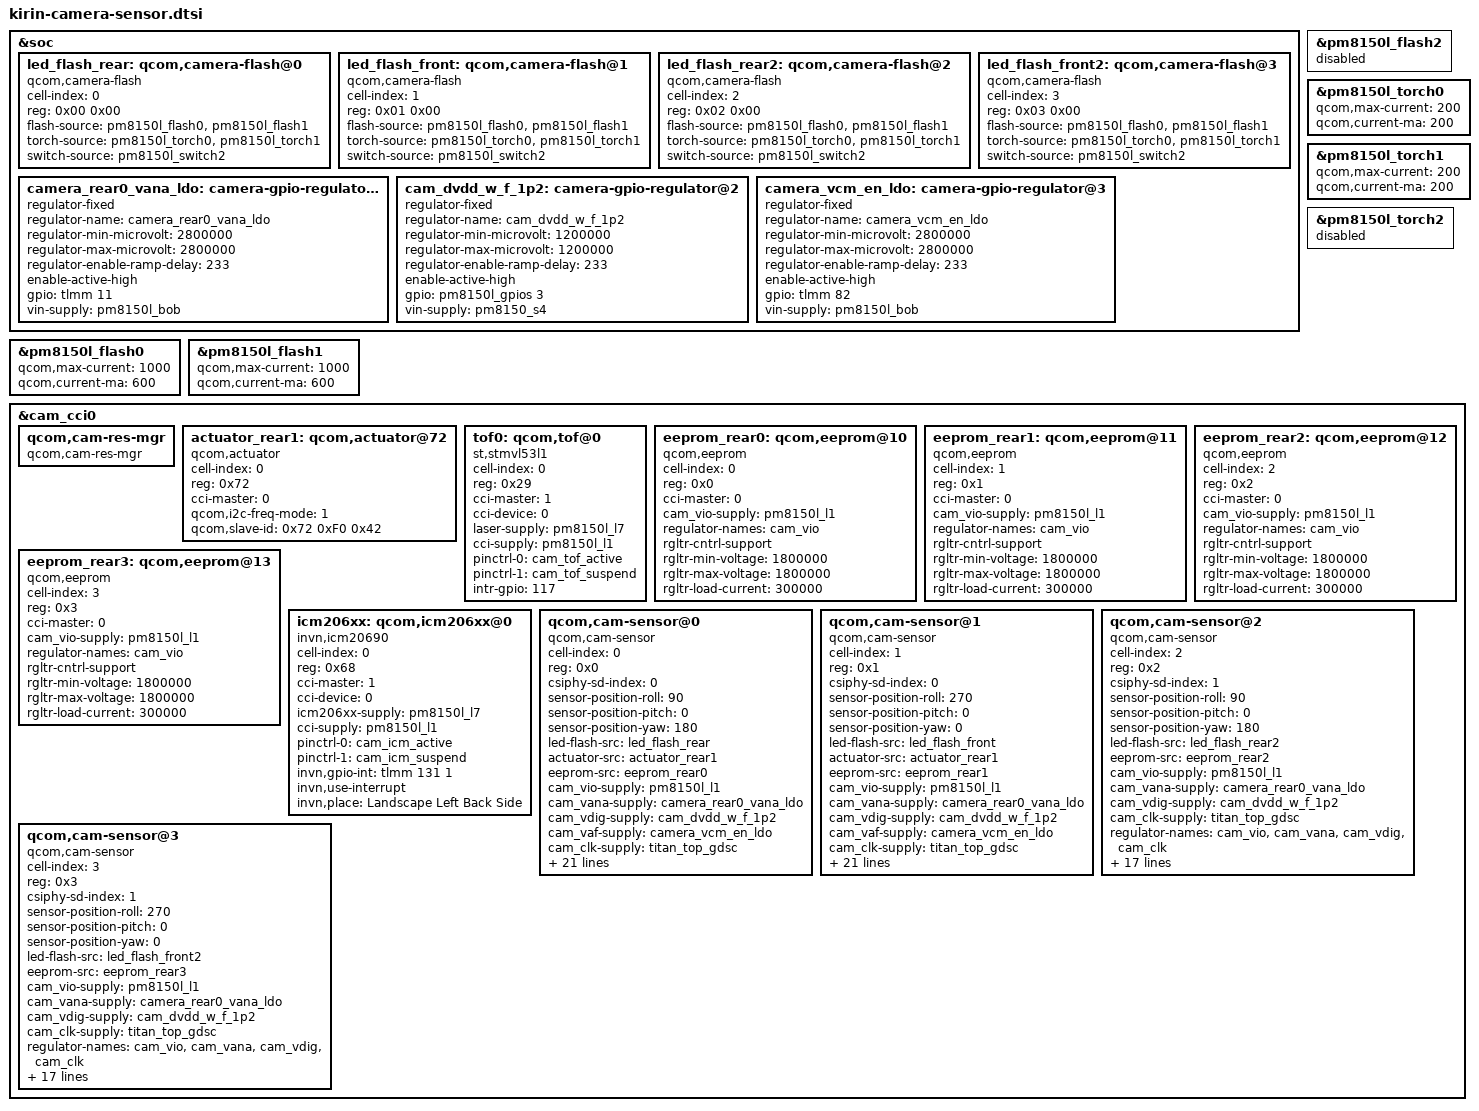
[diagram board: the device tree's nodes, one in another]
/*
 * Copyright (c) 2018, The Linux Foundation. All rights reserved.
 *
 * This program is free software; you can redistribute it and/or modify
 * it under the terms of the GNU General Public License version 2 and
 * only version 2 as published by the Free Software Foundation.
 *
 * This program is distributed in the hope that it will be useful,
 * but WITHOUT ANY WARRANTY; without even the implied warranty of
 * MERCHANTABILITY or FITNESS FOR A PARTICULAR PURPOSE.  See the
 * GNU General Public License for more details.
 */


&soc {
	led_flash_rear: qcom,camera-flash@0 {
		cell-index = <0>;
		reg = <0x00 0x00>;
		compatible = "qcom,camera-flash";
		flash-source = <&pm8150l_flash0 &pm8150l_flash1>;
		torch-source = <&pm8150l_torch0 &pm8150l_torch1>;
		switch-source = <&pm8150l_switch2>;
		status = "ok";
	};
	led_flash_front: qcom,camera-flash@1 {
		cell-index = <1>;
		reg = <0x01 0x00>;
		compatible = "qcom,camera-flash";
		flash-source = <&pm8150l_flash0 &pm8150l_flash1>;
		torch-source = <&pm8150l_torch0 &pm8150l_torch1>;
		switch-source = <&pm8150l_switch2>;
		status = "ok";
	};
	led_flash_rear2: qcom,camera-flash@2 {
		cell-index = <2>;
		reg = <0x02 0x00>;
		compatible = "qcom,camera-flash";
		flash-source = <&pm8150l_flash0 &pm8150l_flash1>;
		torch-source = <&pm8150l_torch0 &pm8150l_torch1>;
		switch-source = <&pm8150l_switch2>;
		status = "ok";
	};
	led_flash_front2: qcom,camera-flash@3 {
		cell-index = <3>;
		reg = <0x03 0x00>;
		compatible = "qcom,camera-flash";
		flash-source = <&pm8150l_flash0 &pm8150l_flash1>;
		torch-source = <&pm8150l_torch0 &pm8150l_torch1>;
		switch-source = <&pm8150l_switch2>;
		status = "ok";
	};
};
//ASUS_BSP flash +++
&pm8150l_flash0 {
	qcom,max-current = <1000>;
	qcom,current-ma = <600>;
};

&pm8150l_flash1 {
	qcom,max-current = <1000>;
	qcom,current-ma = <600>;
};

&pm8150l_flash2 {
	status = "disabled";
};

&pm8150l_torch0 {
	qcom,max-current = <200>;
	qcom,current-ma = <200>;
};

&pm8150l_torch1 {
	qcom,max-current = <200>;
	qcom,current-ma = <200>;
};

&pm8150l_torch2 {
	status = "disabled";
};

//ASUS_BSP flash ---
&soc {
	camera_rear0_vana_ldo: camera-gpio-regulator@0 {
		compatible = "regulator-fixed";
		regulator-name = "camera_rear0_vana_ldo";
		regulator-min-microvolt = <2800000>;
		regulator-max-microvolt = <2800000>;
		regulator-enable-ramp-delay = <233>;
		enable-active-high;
		gpio = <&tlmm 11 0>;
		vin-supply = <&pm8150l_bob>;
	};
	cam_dvdd_w_f_1p2: camera-gpio-regulator@2 {
		compatible = "regulator-fixed";
		regulator-name = "cam_dvdd_w_f_1p2";
		regulator-min-microvolt = <1200000>;
		regulator-max-microvolt = <1200000>;
		regulator-enable-ramp-delay = <233>;
		enable-active-high;
		gpio = <&pm8150l_gpios 3 0>;
		vin-supply = <&pm8150_s4>;
	};
	camera_vcm_en_ldo: camera-gpio-regulator@3 {
		compatible = "regulator-fixed";
		regulator-name = "camera_vcm_en_ldo";
		regulator-min-microvolt = <2800000>;
		regulator-max-microvolt = <2800000>;
		regulator-enable-ramp-delay = <233>;
		enable-active-high;
		gpio = <&tlmm 82 0>;
		vin-supply = <&pm8150l_bob>;
	};
};
&cam_cci0 {
	qcom,cam-res-mgr {
		compatible = "qcom,cam-res-mgr";
		status = "ok";
	};

	actuator_rear1: qcom,actuator@72 {
		cell-index = <0>;
		reg = <0x72>;
		compatible = "qcom,actuator";
		cci-master = <0>;
		qcom,i2c-freq-mode = <1>;
		qcom,slave-id = <0x72 0xF0 0x42>;
		status = "ok";
	};

        //ASUS_BSP Byron porting ST Laser +++
	tof0: qcom,tof@0{
		cell-index = <0>;
		reg = <0x29>; //<0x52>>1>
		compatible = "st,stmvl53l1";
		cci-master = <1>;
		cci-device = <0>; //ASUS_BSP Byron <mean cam_cci0 not cci master 0>
		laser-supply = <&pm8150l_l7>;
		cci-supply = <&pm8150l_l1>;
		pinctrl-names = "cam_default", "cam_suspend";
		pinctrl-0 = <&cam_tof_active>;
		pinctrl-1 = <&cam_tof_suspend>;
		intr-gpio = <117>;
		//xsdn-gpio = <10>;
	};
        //ASUS_BSP Byron porting ST Laser ---

	eeprom_rear0: qcom,eeprom@10 {
		cell-index = <0>;
		reg = <0x0>;
		cci-master = <0>;
		compatible = "qcom,eeprom";
		cam_vio-supply = <&pm8150l_l1>;
		regulator-names = "cam_vio";
		rgltr-cntrl-support;
		rgltr-min-voltage = <1800000>;
		rgltr-max-voltage = <1800000>;
		rgltr-load-current = <300000>;
		status = "ok";
	};

	eeprom_rear1: qcom,eeprom@11 {
		cell-index = <1>;
		reg = <0x1>;
		cci-master = <0>;
		compatible = "qcom,eeprom";
		cam_vio-supply = <&pm8150l_l1>;
		regulator-names = "cam_vio";
		rgltr-cntrl-support;
		rgltr-min-voltage = <1800000>;
		rgltr-max-voltage = <1800000>;
		rgltr-load-current = <300000>;
		status = "ok";
	};

	eeprom_rear2: qcom,eeprom@12 {
		cell-index = <2>;
		reg = <0x2>;
		cci-master = <0>;
		compatible = "qcom,eeprom";
		cam_vio-supply = <&pm8150l_l1>;
		regulator-names = "cam_vio";
		rgltr-cntrl-support;
		rgltr-min-voltage = <1800000>;
		rgltr-max-voltage = <1800000>;
		rgltr-load-current = <300000>;
		status = "ok";
	};

	eeprom_rear3: qcom,eeprom@13 {
		cell-index = <3>;
		reg = <0x3>;
		cci-master = <0>;
		compatible = "qcom,eeprom";
		cam_vio-supply = <&pm8150l_l1>;
		regulator-names = "cam_vio";
		rgltr-cntrl-support;
		rgltr-min-voltage = <1800000>;
		rgltr-max-voltage = <1800000>;
		rgltr-load-current = <300000>;
		status = "ok";
	};
        /* icm206xx +++++ */
        icm206xx: qcom,icm206xx@0 {
                cell-index = <0>;
                reg = <0x68>;
                compatible = "invn,icm20690";
                cci-master = <1>;
                cci-device = <0>;
                icm206xx-supply = <&pm8150l_l7>;
                cci-supply = <&pm8150l_l1>;
                pinctrl-names = "cam_default", "cam_suspend";
                pinctrl-0 = <&cam_icm_active>;
                pinctrl-1 = <&cam_icm_suspend>;
                invn,gpio-int = <&tlmm 131 1>;
                invn,use-interrupt;
                invn,place = "Landscape Left Back Side";
        };
        /* icm206xx ----- */
	qcom,cam-sensor@0 {
		cell-index = <0>;
		compatible = "qcom,cam-sensor";
		reg = <0x0>;
		csiphy-sd-index = <0>;
		sensor-position-roll = <90>;
		sensor-position-pitch = <0>;
		sensor-position-yaw = <180>;
		led-flash-src = <&led_flash_rear>;
		actuator-src = <&actuator_rear1>;
		eeprom-src = <&eeprom_rear0>;
		cam_vio-supply = <&pm8150l_l1>;
		cam_vana-supply = <&camera_rear0_vana_ldo>;
		cam_vdig-supply = <&cam_dvdd_w_f_1p2>;
		cam_vaf-supply = <&camera_vcm_en_ldo>;
		cam_clk-supply = <&titan_top_gdsc>;
		regulator-names = "cam_vio", "cam_vana", "cam_vdig", "cam_vaf", "cam_clk";
		rgltr-cntrl-support;
		rgltr-min-voltage = <1800000 2800000 1200000 2800000 0>;
		rgltr-max-voltage = <1800000 2800000 1200000 2800000 0>;
		rgltr-load-current = <0 80000 1200000 0 0 0>;
		gpio-no-mux = <0>;
		pinctrl-names = "cam_default", "cam_suspend";
		pinctrl-0 = <&cam_sensor_mclk0_active>;
		pinctrl-1 = <&cam_sensor_mclk0_suspend>;
		gpios = <&tlmm 13 0>,
			<&tlmm 28 0>;
		gpio-reset = <1>;
		gpio-req-tbl-num = <0 1>;
		gpio-req-tbl-flags = <1 0>;
		gpio-req-tbl-label = "CAMIF_MCLK0",
					"CAM_RESET0";
		sensor-mode = <0>;
		cci-master = <0>;
		status = "ok";
		clocks = <&clock_camcc CAM_CC_MCLK0_CLK>;
		clock-names = "cam_clk";
		clock-cntl-level = "turbo";
		clock-rates = <19200000>;
	};
	qcom,cam-sensor@1 {
		cell-index = <1>;
		compatible = "qcom,cam-sensor";
		reg = <0x1>;
		csiphy-sd-index = <0>;
		sensor-position-roll = <270>;
		sensor-position-pitch = <0>;
		sensor-position-yaw = <0>;
		led-flash-src = <&led_flash_front>;
		actuator-src = <&actuator_rear1>;
		eeprom-src = <&eeprom_rear1>;
		cam_vio-supply = <&pm8150l_l1>;
		cam_vana-supply = <&camera_rear0_vana_ldo>;
		cam_vdig-supply = <&cam_dvdd_w_f_1p2>;
		cam_vaf-supply = <&camera_vcm_en_ldo>;
		cam_clk-supply = <&titan_top_gdsc>;
		regulator-names = "cam_vio", "cam_vana", "cam_vdig", "cam_vaf", "cam_clk";
		rgltr-cntrl-support;
		rgltr-min-voltage = <1800000 2800000 1200000 2800000 0>;
		rgltr-max-voltage = <1800000 2800000 1200000 2800000 0>;
		rgltr-load-current = <0 80000 1200000 0 0 0>;
		gpio-no-mux = <0>;
		pinctrl-names = "cam_default", "cam_suspend";
		pinctrl-0 = <&cam_sensor_mclk0_active>;
		pinctrl-1 = <&cam_sensor_mclk0_suspend>;
		gpios = <&tlmm 13 0>,
			<&tlmm 28 0>;
		gpio-reset = <1>;
		gpio-req-tbl-num = <0 1>;
		gpio-req-tbl-flags = <1 0>;
		gpio-req-tbl-label = "CAMIF_MCLK0",
					"CAM_RESET0";
		sensor-mode = <0>;
		cci-master = <0>;
		status = "ok";
		clocks = <&clock_camcc CAM_CC_MCLK0_CLK>;
		clock-names = "cam_clk";
		clock-cntl-level = "turbo";
		clock-rates = <19200000>;
	};
	qcom,cam-sensor@2 {
		cell-index = <2>;
		compatible = "qcom,cam-sensor";
		reg = <0x2>;
		csiphy-sd-index = <1>;
		sensor-position-roll = <90>;
		sensor-position-pitch = <0>;
		sensor-position-yaw = <180>;
		led-flash-src = <&led_flash_rear2>;
		eeprom-src = <&eeprom_rear2>;
		cam_vio-supply = <&pm8150l_l1>;
		cam_vana-supply = <&camera_rear0_vana_ldo>;
		cam_vdig-supply = <&cam_dvdd_w_f_1p2>;
		cam_clk-supply = <&titan_top_gdsc>;
		regulator-names = "cam_vio", "cam_vana", "cam_vdig",
			"cam_clk";
		rgltr-cntrl-support;
		rgltr-min-voltage = <1800000 2800000 1200000 0>;
		rgltr-max-voltage = <1800000 2800000 1200000 0>;
		rgltr-load-current = <0 80000 1200000 0>;
		gpio-no-mux = <0>;
		pinctrl-names = "cam_default", "cam_suspend";
		pinctrl-0 = <&cam_sensor_mclk1_active>;
		pinctrl-1 = <&cam_sensor_mclk1_suspend>;
		gpios = <&tlmm 14 0>,
			<&tlmm 30 0>;
		gpio-reset = <1>;
		gpio-req-tbl-num = <0 1>;
		gpio-req-tbl-flags = <1 0>;
		gpio-req-tbl-label = "CAMIF_MCLK1",
					"CAM_RESET1";
		sensor-mode = <0>;
		cci-master = <1>;
		status = "ok";
		clocks = <&clock_camcc CAM_CC_MCLK1_CLK>;
		clock-names = "cam_clk";
		clock-cntl-level = "turbo";
		clock-rates = <19200000>;
	};
	qcom,cam-sensor@3 {
		cell-index = <3>;
		compatible = "qcom,cam-sensor";
		reg = <0x3>;
		csiphy-sd-index = <1>;
		sensor-position-roll = <270>;
		sensor-position-pitch = <0>;
		sensor-position-yaw = <0>;
		led-flash-src = <&led_flash_front2>;
		eeprom-src = <&eeprom_rear3>;
		cam_vio-supply = <&pm8150l_l1>;
		cam_vana-supply = <&camera_rear0_vana_ldo>;
		cam_vdig-supply = <&cam_dvdd_w_f_1p2>;
		cam_clk-supply = <&titan_top_gdsc>;
		regulator-names = "cam_vio", "cam_vana", "cam_vdig",
			"cam_clk";
		rgltr-cntrl-support;
		rgltr-min-voltage = <1800000 2800000 1200000 0>;
		rgltr-max-voltage = <1800000 2800000 1200000 0>;
		rgltr-load-current = <0 80000 1200000 0>;
		gpio-no-mux = <0>;
		pinctrl-names = "cam_default", "cam_suspend";
		pinctrl-0 = <&cam_sensor_mclk1_active>;
		pinctrl-1 = <&cam_sensor_mclk1_suspend>;
		gpios = <&tlmm 14 0>,
			<&tlmm 30 0>;
		gpio-reset = <1>;
		gpio-req-tbl-num = <0 1>;
		gpio-req-tbl-flags = <1 0>;
		gpio-req-tbl-label = "CAMIF_MCLK1",
					"CAM_RESET1";
		sensor-mode = <0>;
		cci-master = <1>;
		status = "ok";
		clocks = <&clock_camcc CAM_CC_MCLK1_CLK>;
		clock-names = "cam_clk";
		clock-cntl-level = "turbo";
		clock-rates = <19200000>;
	};
};
